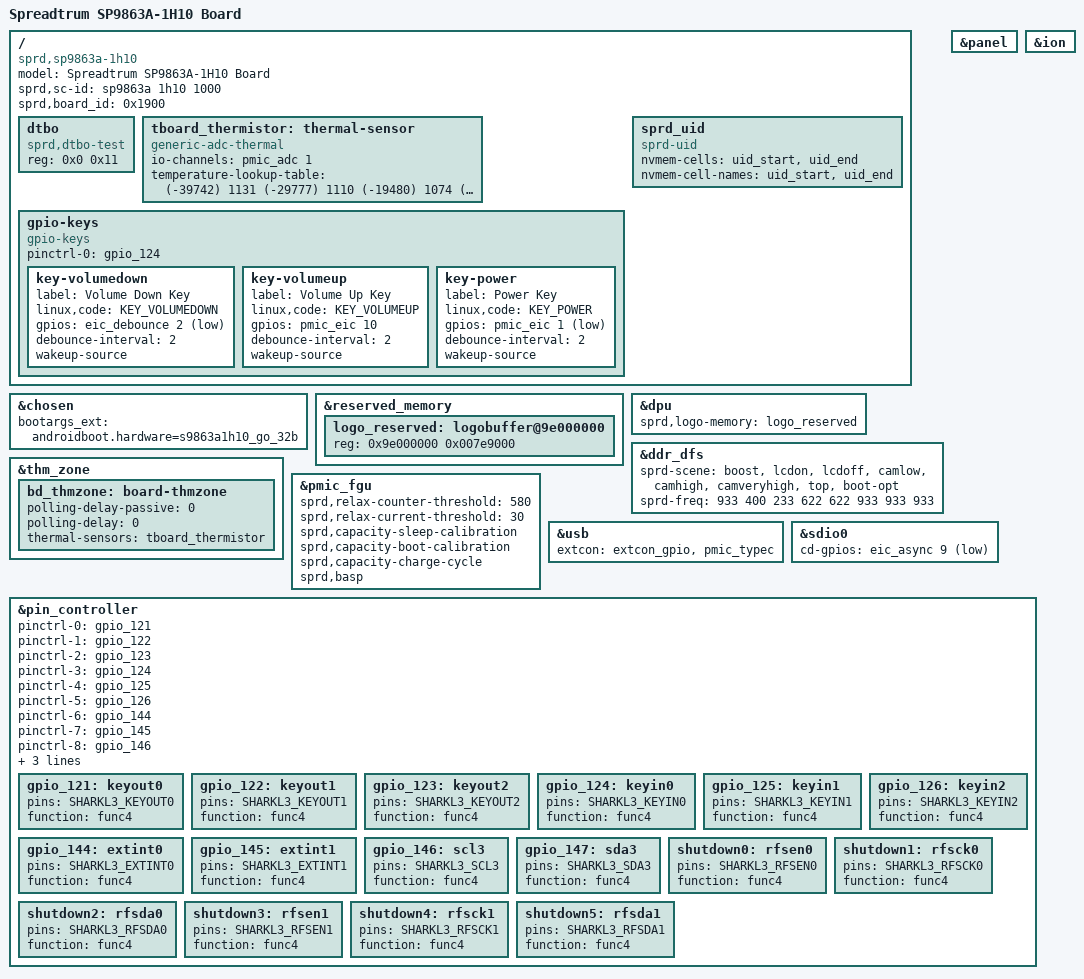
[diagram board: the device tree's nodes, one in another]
/dts-v1/;
/plugin/;
#include <dt-bindings/input/input.h>
#include <dt-bindings/gpio/gpio.h>
#include <dt-bindings/clock/sprd,sc9863a-clk.h>
#include "zte_lcd_lead_st7701s_ctc_5p99_480p.dtsi"
#include "zte_lcd_coe_gc9503p_boe_5p99_480p.dtsi"
#include "zte_lcd_neweasyquick_gc9503p_boe_5p99_480p.dtsi"
#include "zte_lcd_easyquick_gc9503p_boe_5p99_480p.dtsi"
#include "zte_lcd_coe_st7701s_ivo_5p99_480p.dtsi"
#include "zte_lcd_skyworth_st7701s_boe_5p99_480p.dtsi"
#include "../lcd/lcd_dummy_mipi.dtsi"

/ {
	model = "Spreadtrum SP9863A-1H10 Board";

	compatible = "sprd,sp9863a-1h10", "sprd,sc9863a";

	sprd,sc-id = "sp9863a 1h10 1000";

	sprd,board_id = <0x1900>; //XX00:base board,XX00~XXFF:customize board

	fragment {
		target-path = "/";
		__overlay__ {
			#address-cells = <1>;
			#size-cells = <1>;
			dtbo: dtbo {
				compatible = "sprd,dtbo-test";
				reg = <0x0 0x11>;
			};

			tboard_thermistor:thermal-sensor {
				compatible = "generic-adc-thermal";
				#thermal-sensor-cells = <0>;
				io-channels = <&pmic_adc 1>;
				io-channel-names = "sensor-channel";
				temperature-lookup-table = < (-39742) 1131
							(-29777) 1110
							(-19480) 1074
							(-4679) 983
							10110 838
							24805 654
							44922 413
							54903 316
							64895 238
							74884 178
							84883 133
							94883 100
							104880 75
							114889 57
							124872 43 >;
			};

			gpio-keys {
				compatible = "gpio-keys";
				pinctrl-names = "gpio_124";
				pinctrl-0 = <&gpio_124>;
				key-volumedown {
					label = "Volume Down Key";
					linux,code = <KEY_VOLUMEDOWN>;
					gpios = <&eic_debounce 2 GPIO_ACTIVE_LOW>;
					debounce-interval = <2>;
					wakeup-source;
				};
				key-volumeup {
					label = "Volume Up Key";
					linux,code = <KEY_VOLUMEUP>;
					gpios = <&pmic_eic 10 GPIO_ACTIVE_HIGH>;
					debounce-interval = <2>;
					wakeup-source;
				};
				key-power {
					label = "Power Key";
					linux,code =<KEY_POWER>;
					gpios = <&pmic_eic 1 GPIO_ACTIVE_LOW>;
					debounce-interval = <2>;
					wakeup-source;
				};
			};
			sprd_uid {
				compatible = "sprd-uid";
				nvmem-cells = <&uid_start>, <&uid_end>;
				nvmem-cell-names = "uid_start", "uid_end";
			};
		};
	};
};

&chosen {
	bootargs_ext = "androidboot.hardware=s9863a1h10_go_32b";
};

&reserved_memory {
	#address-cells = <1>;
	#size-cells = <1>;

	logo_reserved: logobuffer@9e000000 {
		reg = <0x9e000000 0x007e9000>;
	};
};

&dpu {
	sprd,logo-memory = <&logo_reserved>;
};

&ddr_dfs {
	sprd-scene = "boost", "lcdon", "lcdoff", "camlow",
		"camhigh", "camveryhigh", "top", "boot-opt";
	sprd-freq = <933 400 233 622 622 933 933 933>;
};

&panel {
};

&thm_zone {
	bd_thmzone: board-thmzone {
		polling-delay-passive = <0>;
		polling-delay = <0>;
		thermal-sensors = <&tboard_thermistor>;
	};
};







&pmic_fgu {
	sprd,relax-counter-threshold = <580>;
	sprd,relax-current-threshold = <30>;
	sprd,capacity-sleep-calibration;

	sprd,capacity-boot-calibration;
	sprd,capacity-charge-cycle;
	sprd,basp;
};

&usb{
	extcon = <&extcon_gpio>, <&pmic_typec>;
	status = "okay";
};

&sdio0 {
	cd-gpios = <&eic_async 9 1>;
};

&ion {
	#address-cells = <1>;
	#size-cells = <0>;

};

&pin_controller {
	pinctrl-names =
	/* keyout0 ~ keyout2 */
	"gpio_121", "gpio_122", "gpio_123",
	/* keyin0 ~ keyin2 */
	"gpio_124", "gpio_125", "gpio_126",
	/* extint0, extint1, scl3, sda3 */
	"gpio_144", "gpio_145", "gpio_146", "gpio_147",
	/* Note:If create a new board,need to add the shutdown node */
        "shutdown";
	pinctrl-0 = <&gpio_121>;
	pinctrl-1 = <&gpio_122>;
	pinctrl-2 = <&gpio_123>;
	pinctrl-3 = <&gpio_124>;
	pinctrl-4 = <&gpio_125>;
	pinctrl-5 = <&gpio_126>;
	pinctrl-6 = <&gpio_144>;
	pinctrl-7 = <&gpio_145>;
	pinctrl-8 = <&gpio_146>;
	pinctrl-9 = <&gpio_147>;
	pinctrl-10 = <&shutdown0
			&shutdown1
			&shutdown2
			&shutdown3
			&shutdown4
			&shutdown5>;

	gpio_121: keyout0 {
		pins = "SHARKL3_KEYOUT0";
		function = "func4";
	};

	gpio_122: keyout1 {
		pins = "SHARKL3_KEYOUT1";
		function = "func4";
	};

	gpio_123: keyout2 {
		pins = "SHARKL3_KEYOUT2";
		function = "func4";
	};

	gpio_124: keyin0 {
		pins = "SHARKL3_KEYIN0";
		function = "func4";
	};

	gpio_125: keyin1 {
		pins = "SHARKL3_KEYIN1";
		function = "func4";
	};

	gpio_126: keyin2 {
		pins = "SHARKL3_KEYIN2";
		function = "func4";
	};

	gpio_144: extint0 {
		pins = "SHARKL3_EXTINT0";
		function = "func4";
	};

	gpio_145: extint1 {
		pins = "SHARKL3_EXTINT1";
		function = "func4";
	};

	gpio_146: scl3 {
		pins = "SHARKL3_SCL3";
		function = "func4";
	};

	gpio_147: sda3 {
		pins = "SHARKL3_SDA3";
		function = "func4";
	};

	shutdown0: rfsen0 {
		pins = "SHARKL3_RFSEN0";
		function = "func4";
	};

	shutdown1: rfsck0 {
		pins = "SHARKL3_RFSCK0";
		function = "func4";
	};

	shutdown2: rfsda0 {
		pins = "SHARKL3_RFSDA0";
		function = "func4";
	};

	shutdown3: rfsen1 {
		pins = "SHARKL3_RFSEN1";
		function = "func4";
	};

	shutdown4: rfsck1 {
		pins = "SHARKL3_RFSCK1";
		function = "func4";
	};

	shutdown5: rfsda1 {
		pins = "SHARKL3_RFSDA1";
		function = "func4";
	};
};
